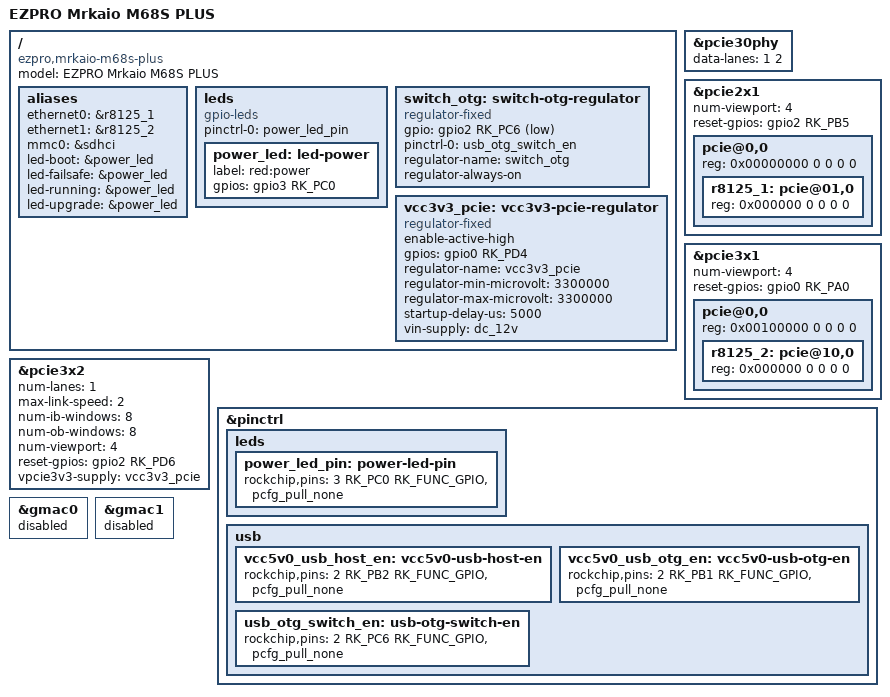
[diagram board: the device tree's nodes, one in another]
// SPDX-License-Identifier: (GPL-2.0+ OR MIT)
// Copyright (c) 2023 mleaf <mleaf90@gmail.com>

/dts-v1/;

#include "rk3568-mrkaio-m68s-core.dtsi"

/ {
	model = "EZPRO Mrkaio M68S PLUS";
	compatible = "ezpro,mrkaio-m68s-plus", "rockchip,rk3568";

	aliases {
		ethernet0 = &r8125_1;
		ethernet1 = &r8125_2;
		mmc0 = &sdhci;
		led-boot = &power_led;
		led-failsafe = &power_led;
		led-running = &power_led;
		led-upgrade = &power_led;
	};

	leds {
		compatible = "gpio-leds";
		pinctrl-names = "default";
		pinctrl-0 = <&power_led_pin>;

		power_led: led-power {
			label = "red:power";
			gpios = <&gpio3 RK_PC0 GPIO_ACTIVE_HIGH>;
		};
	};

	switch_otg: switch-otg-regulator {
		compatible = "regulator-fixed";
		gpio = <&gpio2 RK_PC6 GPIO_ACTIVE_LOW>;
		pinctrl-names = "default";
		pinctrl-0 = <&usb_otg_switch_en>;
		regulator-name = "switch_otg";
		regulator-always-on;
	};

	vcc3v3_pcie: vcc3v3-pcie-regulator {
		compatible = "regulator-fixed";
		enable-active-high;
		gpios = <&gpio0 RK_PD4 GPIO_ACTIVE_HIGH>;
		regulator-name = "vcc3v3_pcie";
		regulator-min-microvolt = <3300000>;
		regulator-max-microvolt = <3300000>;
		startup-delay-us = <5000>;
		vin-supply = <&dc_12v>;
	};
};

&pcie30phy {
	data-lanes = <1 2>;
	status = "okay";
};

&pcie2x1 {
	num-viewport = <4>;
	reset-gpios = <&gpio2 RK_PB5 GPIO_ACTIVE_HIGH>;
	status = "okay";

	pcie@0,0 {
		reg = <0x00000000 0 0 0 0>;
		#address-cells = <3>;
		#size-cells = <2>;

		r8125_1: pcie@01,0 {
			reg = <0x000000 0 0 0 0>;
		};
	};
};

&pcie3x1 {
	num-viewport = <4>;
	reset-gpios = <&gpio0 RK_PA0 GPIO_ACTIVE_HIGH>;
	status = "okay";

	pcie@0,0 {
		reg = <0x00100000 0 0 0 0>;
		#address-cells = <3>;
		#size-cells = <2>;

		r8125_2: pcie@10,0 {
			reg = <0x000000 0 0 0 0>;
		};
	};
};

&pcie3x2 {
	num-lanes = <1>;
	max-link-speed = <2>;
	num-ib-windows = <8>;
	num-ob-windows = <8>;
	num-viewport = <4>;
	reset-gpios = <&gpio2 RK_PD6 GPIO_ACTIVE_HIGH>;
	vpcie3v3-supply = <&vcc3v3_pcie>;
	status = "okay";
};

&pinctrl {
	leds {
		power_led_pin: power-led-pin {
			rockchip,pins = <3 RK_PC0 RK_FUNC_GPIO &pcfg_pull_none>;
		};
	};

	usb {
		vcc5v0_usb_host_en: vcc5v0-usb-host-en {
			rockchip,pins = <2 RK_PB2 RK_FUNC_GPIO &pcfg_pull_none>;
		};

		vcc5v0_usb_otg_en: vcc5v0-usb-otg-en {
			rockchip,pins = <2 RK_PB1 RK_FUNC_GPIO &pcfg_pull_none>;
		};

		usb_otg_switch_en: usb-otg-switch-en {
			rockchip,pins = <2 RK_PC6 RK_FUNC_GPIO &pcfg_pull_none>;
		};
	};
};

&gmac0 {
	status = "disabled";
};

&gmac1 {
	status = "disabled";
};
